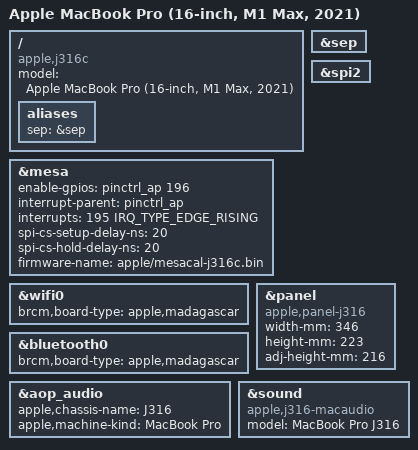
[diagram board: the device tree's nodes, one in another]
// SPDX-License-Identifier: GPL-2.0+ OR MIT
/*
 * MacBook Pro (16-inch, M1 Max, 2021)
 *
 * target-type: J316c
 *
 * Copyright The Asahi Linux Contributors
 */

/dts-v1/;

/*
 * PMP manages system power states. This board has run sustained ANE and GPU
 * measurement lanes with PMP enabled; s2idle resume qualification is tracked
 * on the pull request.
 */
#define APPLE_USE_PMP

#include "t6001.dtsi"
#include "t600x-j314-j316.dtsi"

/ {
	compatible = "apple,j316c", "apple,t6001", "apple,arm-platform";
	model = "Apple MacBook Pro (16-inch, M1 Max, 2021)";

	aliases {
		sep = &sep;
	};
};

/*
 * m1n1 keys off the sep alias to add the sepfw region and the boot
 * manifests the driver needs to cold-boot SEPOS.
 */
&sep {
	status = "okay";
};

/*
 * The J314s/J316s lines, read from those machines' platform device trees
 * (/arm-io/spi2/mesa) and identical on the 14" and 16" M1 Pro: the power
 * line is gpio0 pin 196 (function-mesa_pwr, active high) and the data-ready
 * line is pin 195. The M1 Max boards share this family's board file,
 * t600x-j314-j316.dtsi. J316c's own platform device tree has not been
 * checked yet, and J316c is untested.
 */
&spi2 {
	status = "okay";
};

&mesa {
	status = "okay";
	enable-gpios = <&pinctrl_ap 196 GPIO_ACTIVE_HIGH>;
	interrupt-parent = <&pinctrl_ap>;
	interrupts = <195 IRQ_TYPE_EDGE_RISING>;
	spi-cs-setup-delay-ns = <20>;
	spi-cs-hold-delay-ns = <20>;
	/*
	 * Per-device factory data, extracted from this machine's own macOS
	 * install; it is not redistributable.
	 */
	firmware-name = "apple/mesacal-j316c.bin";
};

&wifi0 {
	brcm,board-type = "apple,madagascar";
};

&bluetooth0 {
	brcm,board-type = "apple,madagascar";
};

&panel {
	compatible = "apple,panel-j316", "apple,panel-mini-led", "apple,panel";
	width-mm = <346>;
	height-mm = <223>;
	adj-height-mm = <216>;
};

&aop_audio {
	apple,chassis-name = "J316";
	apple,machine-kind = "MacBook Pro";
};

&sound {
	compatible = "apple,j316-macaudio", "apple,macaudio";
	model = "MacBook Pro J316";
};
